# ISP6P5_SYS3 register map
Vendor: Texas Instruments
Peripheral module from a debugger description file (folder DM50x).
Registers are 32-bit, access per field, reset 0x0 unless marked. A register's access mark holds for its fields unless they carry their own. Offsets are as the file gives them; lines under a group give offsets from that group; [hi:lo] are bit positions; {n}, {i} and the like mark numbered series; 'fields as' and 'values as' point back to an identical list; <NAME> marks a mode.

## ISP6P5_SYS3
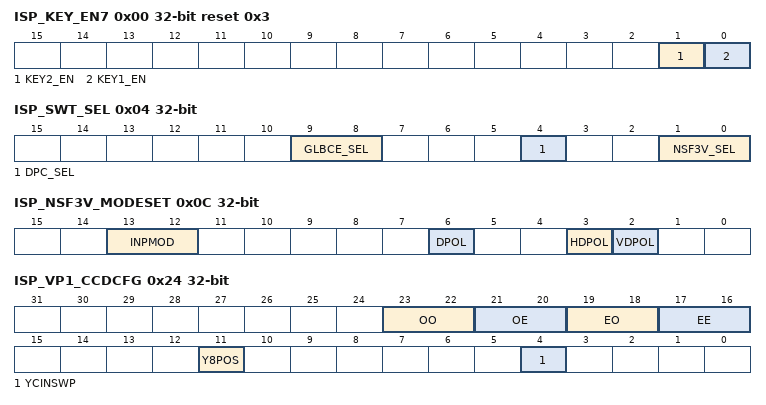
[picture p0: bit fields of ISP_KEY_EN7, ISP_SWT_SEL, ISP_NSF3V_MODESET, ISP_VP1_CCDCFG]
0x00 ISP_KEY_EN7 ro reset 0x3 — GLBCE eFuse enable.
  [1] KEY2_EN — EFUSE enable Equals 1 when ISP5_EFUSE6_EN = 1. Equals 0 otherwise. 1'b1 means GLBCE Decomapding function is present in HW 1'b0 means GLBCE Decomapding function is not present in HW
    0=DISABLE (GLBCE Disable); 1=ENABLE (GLBCE Enable)
  [0] KEY1_EN — EFUSE Enable. Equals 1 when ISP5_EFUSE5_EN = 1. Equals 0 otherwise. 1'b1 means GLBCE function is present in HW 1'b0 means GLBCE function is not present in HW
    0=DISABLE (GLBCE Disable); 1=ENABLE (GLBCE Enable)
0x04 ISP_SWT_SEL — Controls the Switch block in ISP-Top.
  [9:8] GLBCE_SEL rw — Select GLBCE Module processing order
    0=DISABLE (Disable data passing to GLBCE ISP6 works same way as ISP6 without GLBCE function.); 1=CAL (Enable GLBCE with CAL); 2=ISP (Enable GLBCE before IPIPE (VP-2 path))
  [4] DPC_SEL rw
    0=DISABLE (DPC before NSF3V is disabled.); 1=ENABLE (DPC in NSF3V path is enabled. valid only if NSF3V_SEL=1 or 2. To actually activate the function, dpc function in IPIPE must be properly configured.)
  [1:0] NSF3V_SEL rw — Select NSF3V Module processing order
    0=DISABLE (Disable data passing to NSF3V. ISP6 works same way as ISP6 without NSF3V function.); 1=CAL (Enable NSF3V with CAL); 2=ISP (Enable NSF3V before ISIF in VP-1 path)
0x0C ISP_NSF3V_MODESET — Note: This entry is not shadowed
  [13:12] INPMOD rw — Data input mode for NSF3V (VP-1 and CAL-1) For CAL, this value must be either 0 (RAW) or 1 (8bit) This bit can be changed only when NSF3V is in idle. When switching to 16bit-YCbCr, PCLK must be equal to or less than 1/2 of FCLK.
    0=NEWENUM1 (RAW data); 1=NEWENUM2 (YCbCr 16bit - VP-1 YUV422 16bit YUV420-Y 8bit (although this is 8bit, it is treated as 16bit mode since Y is mapeed to MSB 8bit of 16bit bus) - CAL This value is not valid); 3=NEWENUM4 (Reserved); 2=NEWENUM3 (YCbCr 8bit - CAL YUV422 8bit YUV420-Y 8bit YUV420-C 8bit - VP-1: YUV422 8bit YUV420-C 8bit)
  [6] DPOL rw — Image sensor input data polarity (only for VP-1)
    0=NEWENUM1 (No change); 1=NEWENUM2 (One's complement)
  [3] HDPOL rw — HD Sync Signal Polarity of input signal (only for VP-1) Switch will convert HD polarity to high active regardless of the input polarity
    0=NEWENUM1 (Positive); 1=NEWENUM2 (Negative)
  [2] VDPOL rw — VD Sync Signal Polarity of input signal (Only for VP-1) Switch will convert VD polarity to high active regardless of the input polarity
    0=NEWENUM1 (Positive); 1=NEWENUM2 (Negative)
0x10 ISP_VP1_SPH — Start Pixel Horizontal
  [14:0] SPH rw — The location of the first active pixel in a line. This is specified by the number of cycles. This register is latched at VD or at corresponding SYNCEN rising edge
0x14 ISP_VP1_LNH — This register is latched at VD or at corresponding SYNCEN rising edge
  [14:0] LNH rw — Number of active pixels in an line Number of pixels = LNH + 1. This number is specified by the number of cycles. Therefore, for YUV422 8bit mode, the number of pixels is (LNH+1)/2. This register is latched at VD or at corresponding SYNCEN rising edge
0x18 ISP_VP1_SLV — Start Line, Vertical
  [14:0] SLV rw — Start Line, Vertical Sets line at which active data will begin, measured from the start of VD This register is latched at VD or at corresponding SYNCEN rising edge
0x1C ISP_VP1_LNV
  [14:0] LNV rw — The number of active lines Number of lines = LNV + 1 This register is latched at VD or at corresponding SYNCEN rising edge
0x20 ISP_NSF3V_CGAMMAWD
  [4:1] GWDI rw — Selects MSB position of Input Data for NSF3V (VP-1 and CAL) For input of IN[15..0], corresponding output is given to DPC and/or NSF3V. This bit is only valid in Bayer (RAW) mode. In YUV input, this bit is ignored. There is no GWDO for NSF3V process, since 12 bit is always mapped to LSB.
    6=BIT9 (OUTPUT: (IN[9..0] 2)); 1=BIT14 (OUTPUT: IN[14..3]); 7=BIT8 (OUTPUT: (IN[8..0] 3)); 0=BIT15 (OUTPUT: IN[15..4]); 2=BIT13 (OUTPUT: IN[13..2]); 8=BIT7 (OUTPUT: (IN[7..0] 4)); 9=NEWENUM10 (Reserved); 4=BIT11 (OUTPUT: IN[11..0]); 5=BIT10 (OUTPUT: (IN[10..0] 1)); 3=BIT12 (OUTPUT: IN[12..1])
0x24 ISP_VP1_CCDCFG
  [23:22] OO rw — The color pattern of the odd line and odd pixel used in DPC This parameter is valid when NSF3V_SEL=1 or 2, and DPC_SEL=1.
    0=R; 1=GR; 3=B; 2=GB
  [21:20] OE rw — The color pattern of the odd line and even pixel used in DPC This parameter is valid when NSF3V_SEL=1 or 2, and DPC_SEL=1.
    0=R; 1=GR; 3=B; 2=GB
  [19:18] EO rw — The color pattern of the even line and odd pixel used in DPC This parameter is valid when NSF3V_SEL=1 or 2, and DPC_SEL=1.
    0=R; 1=GR; 3=B; 2=GB
  [17:16] EE rw — The color pattern of the even line and even pixel used in DPC This parameter is valid when NSF3V_SEL=1 or 2, and DPC_SEL=1.
    0=R; 1=GR; 3=B; 2=GB
  [11] Y8POS rw — Selects Y signal position when in 8bit input mode
    0=EVEN (Y is at even pixel Y is at 0th, 2nd, 4th, ... pixels. Cb is at 1st, 5th, ... pixels. Cr is at 3rd, 7th, ... pixels.); 1=ODD (Y is at odd pixel Cb is at 0th, 4th, 8th, ... pixels Cr is at 2nd, 6th, 10th, ... pixels Y is at 1st, 3rd, 5th, ... pixels)
  [4] YCINSWP rw — The ISIF module has a 16-bit interface. When 16-bit YUV data are input, the luma data (YIN7-0) are expected to be on the 8 MS bits and the chroma (CIN7-0) data are expected to be on the LS bits. This bit enables to swap the 8 MS bits with the 8 LS bits of the interface in case the luma and chroma do not come in the correct order. (This function is same as ISIF's. Refer to the top-level ISIF block diagram.)
    0=NEWENUM1 (YIN7-0 = Y signal / CIN7-0 = C signal); 1=NEWENUM2 (YIN7-0 = C signal / CIN7-0 = Y signal)
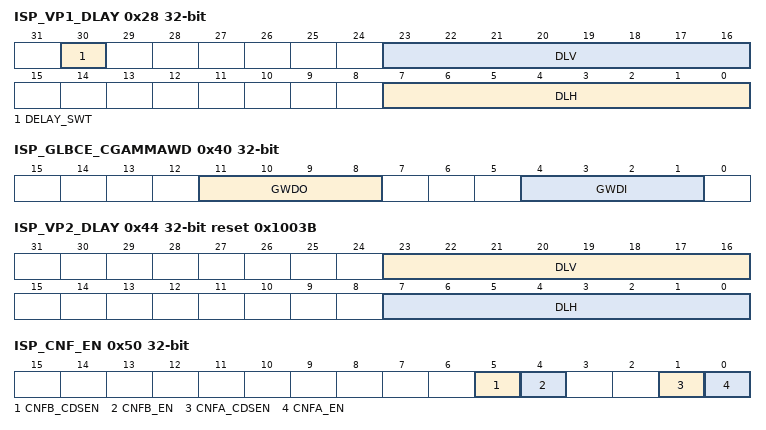
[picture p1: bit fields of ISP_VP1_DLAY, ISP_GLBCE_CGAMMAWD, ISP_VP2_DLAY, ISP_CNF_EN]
0x28 ISP_VP1_DLAY — Horizontal/Vertical Delay of VP1 port
  [30] DELAY_SWT rw — This bit changes the delay between NSF3V input VD/HD and output VD/HD Usually, this bit is '0'. This bit is supposed to be used when NSF3V works with ISP (VP1), and IPIPEIF is in DFS/WDR mode. In this case VD must be at least one line earlier than the first valid line.
    0=DISABLE (The output of VD (VD_OUT) is at the same clock as the first pixel output of the frame. The output of HD (HD_OUT)is at the same clock as the firlst pixel output in each line.); 1=ENABLE (The VD/HD timing is controlled by DLV/DLH. VD output (VD_OUT) timing is DLV lines after VD input (VD_IN), on the same clock as HD output (HD_OUT) HD output (HD_OUT) timing is DLH pixel clocks after HD input (HD_IN))
  [23:16] DLV rw — Vertical Delay of VP1 port from VS_IN to VD_OUT. This field is only used if DELAY_SWT=='1', and ignored if DELAY_SWT=='0' This register is latched at VS. If DELAY_SWT is '1', after number of lines specified here following VD_IN, VD_OUT is output. This value should be equalt to or smaller than NSF3V line latency for meaningfull operation. The only possible case that this field is used is when NSF3V is used with ISP, and IPIPEIF is in DFS or WDR mode. A value between 0 and 3 should be specified for TB_BORDER=00 or 10 case. A value between 0 and 17 should be specified for TB_BODER=01 or 11 case. Since there is DLV lines between VD and the first valid line, the down stream modules need to be programmed accordingly.
  [7:0] DLH rw — This field is only used if DELAY_SWT=='1', and ignored if DELAY_SWT=='0' VP1 port horizontal delay from HS_IN (derived from HD_IN) to HD_OUT, which affect the cycles between HD_OUT and first valid pixel. This register is latched at VS. The meaning of this value changes depending on the input format (ISP_NSF3V_MODESET.INPMOD). For YCbCr-16bit (ISP_NSF3V_MODESET.INPMOD==1) The maximum DLH value allowed is 8. If DLH=8, HD output is at the same clock as the first pixel output in each line. If DLH 8, HD output is (8-DLH) clock before the first pixel output. For Bayer input or YCbCr-8bit input (ISP_NSF3V_MODESET.INPMOD==0 or 2) Maximum DLH allowed is 16. If DLH=16, HD output is at the same clock as the first pixel output in each line. If DLH 16, HD output is (16-DLH) clock before the first pixel output.
0x30 ISP_VP2_SPH — Start Pixel Horizontal
  [14:0] SPH rw — The location of the first active pixel in a line
0x34 RSERVED2 ro — Reserved
0x38 ISP_VP2_SLV — Start Line, Vertical
  fields as ISP_VP1_SLV
0x40 ISP_GLBCE_CGAMMAWD
  [11:8] GWDO rw — Selects MSB position of output data from GLBCE (VP2/CAL2) This value is only used at GLBCE output, and does not affect if GLBCE is skipped (IPIPEIF to IPIPE case).
    6=_10BIT ('000000' [15..6]); 1=_15BIT ('0' [15..1]); 7=_9BIT ('0000000' [15..7]); 0=_16BIT ([15..0]); 2=_14BIT ('00' [15..2]); 8=_8BIT ('00000000' [15..8]); 9=OTHERS (Reserved); 4=_12BIT ('0000' [15..4]); 5=_11BIT ('00000' [15..5]); 3=_13BIT ('000' [15..3])
  [4:1] GWDI rw — Selects MSB position of Input Data for GLBCE (VP2/CAL2) This value is only used at GLBCE input, and does not affect if GLBCE is skipped (IPIPEIF to IPIPE case).
    6=BIT9 ([9..0] '000000'); 1=BIT14 ([14..0] '0'); 7=BIT8 ([8..0] '0000000'); 0=BIT15 ([15..0]); 2=BIT13 ([13..0] '00'); 8=BIT7 ([7..0]*'00000000'); 9=OTHERS (Reserved); 4=BIT11 ([11..0] '0000'); 5=BIT10 ([10..0] '00000'); 3=BIT12 ([12..0] '000')
0x44 ISP_VP2_DLAY reset 0x1003B — Horizontal/Vertical Delay of VP2 port
  [23:16] DLV rw — Vertical Delay of VP1 port from VS_IN to VD_IN. After number of lines specified here following VD_IN, VD_IN is output. This value should be equalt to or smaller than GLBCE line latency for meaningfull operation. This register is latched at VS or at corresponding SYNCEN rising edge Usually, this value should be left as default (1)
  [7:0] DLH rw — VP1 port horizontal delay from HS_IN (derived from HD_IN) to HD_OUT. The latency of NSF3V should be set in this field. This register is latched at VS or at corresponding SYNCEN rising edge Usually, this value should be left as default (67)
0x50 ISP_CNF_EN
  [5] CNFB_CDSEN rw — Note: This is don't care in ISP6.5 since CNF-B is removed. CDS (Chroma down sample) is enabled in CNF process on RZB path. This is only valid if CNF is enabled (RZB_CNFEN=1).
    0=DISABLED (CDS is disabled in CNF process on RZB output); 1=ENABLED (CDS is enabled in CNF process on RZB output)
  [4] CNFB_EN rw — ?WARNING This shouldn't be enabled in ISP6.5 (ADAS-LOW Program) since CNF-B is removed. Enable CNF (Chroma noise filter) on RZB path. This is only valid if the output is 420, and UV pass is active. In other case, this bit must be zero. In specific, this bit is valid in the following cases. 1. YUV420-UV inputRSZ_SRC_FMT1.IN420=1 RSZ_SRC_FMT1.COL=1 2. YUV422 input, YUV420-YUV or YUV420-UV output RSZ_SRC_FMT1.IN420=0 RZB_420.CEN = 1 (RZB_420.YEN can be 0 or 1)
    0=DISABLED (CNF is disabled on RZB output); 1=ENABLED (CNF is enabled on RZB output)
  [1] CNFA_CDSEN rw — CDS (Chroma down sample) is enabled in CNF process on RZA path. This is only valid if CNF is enabled (RZA_CNFEN=1).
    0=DISABLED (CDS is disabled in CNF process on RZA output); 1=ENABLED (CDS is enabled in CNF process on RZA output)
  [0] CNFA_EN rw — Enable CNF (Chroma noise filter) on RZA path This is only valid if the output is 420, and UV pass is active. In other case, this bit must be zero. In specific, this bit is valid in the following cases. 1. YUV420-UV inputRSZ_SRC_FMT1.IN420=1 RSZ_SRC_FMT1.COL=1 2. YUV422 input, YUV420-YUV or YUV420-UV output RSZ_SRC_FMT1.IN420=0 RZA_420.CEN = 1 (RZA_420.YEN can be 0 or 1)
    0=DISABLED (CNF is disabled on RZA output); 1=ENABLED (CNF is enabled on RZA output)
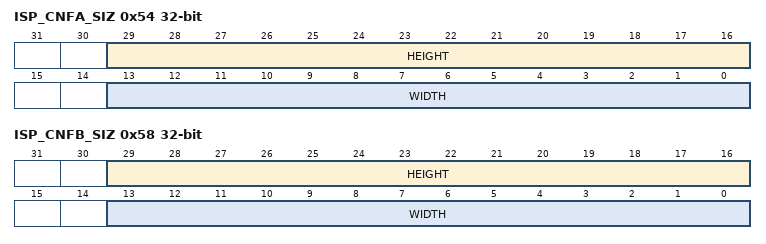
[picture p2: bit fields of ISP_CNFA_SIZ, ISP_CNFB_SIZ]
0x54 ISP_CNFA_SIZ
  [29:16] HEIGHT rw — The height of CNFA output. This number MUST be - Same as Resizer-A chroma output height, if CDS is off - 1/2 of Resizer-A output height, if CDS is on Therefore, the Resizer-A chroma output height must be even if CDS is on. Resizer-A's MMR must be programmed accordingly. This number MUST be the same as CNFA-Core's input height. CNF-A's MMR must be programmed accordingly.
  [13:0] WIDTH rw — The width of CNFA output. This number MUST be even. This number MUST be - Same as Resizer-A output width, if CDS is off - 1/2 of Resizer-A output width, if CDS is on Therefore, the Resizer-A output width must be a multiple of 4 if CDS is on. Resizer-A's MMR must be programmed accordingly. This number MUST be the same as CNFA-Core's input width. CNF-A's MMR must be programmed accordingly.
0x58 ISP_CNFB_SIZ
  [29:16] HEIGHT rw — Note: This is don't care in ISP6.5 since CNF-B is removed. The height of CNFB output. This number MUST be - Same as Resizer-B chroma output height, if CDS is off - 1/2 of Resizer-B chroma output height, if CDS is on Therefore, the Resizer-B chroma output height must be even if CDS is on. Resizer-B's MMR must be programmed accordingly. This number MUST be the same as CNFB-Core's input height. CNF's MMR must be programmed accordingly.
  [13:0] WIDTH rw — Note: This is don't care in ISP6.5 since CNF-B is removed. The width of CNFB output. This number MUST be even. This number MUST be - Same as Resizer-B output width if CDS is off - 1/2 of Resizer-B output width if CDS is on Therefore, the Resizer-B output width must be a multiple of 4 if CDS is on. Resizer-B's MMR must be programmed accordingly. This number MUST be the same as CNFB-Core's input width. CNF-B's MMR must be programmed accordingly.
